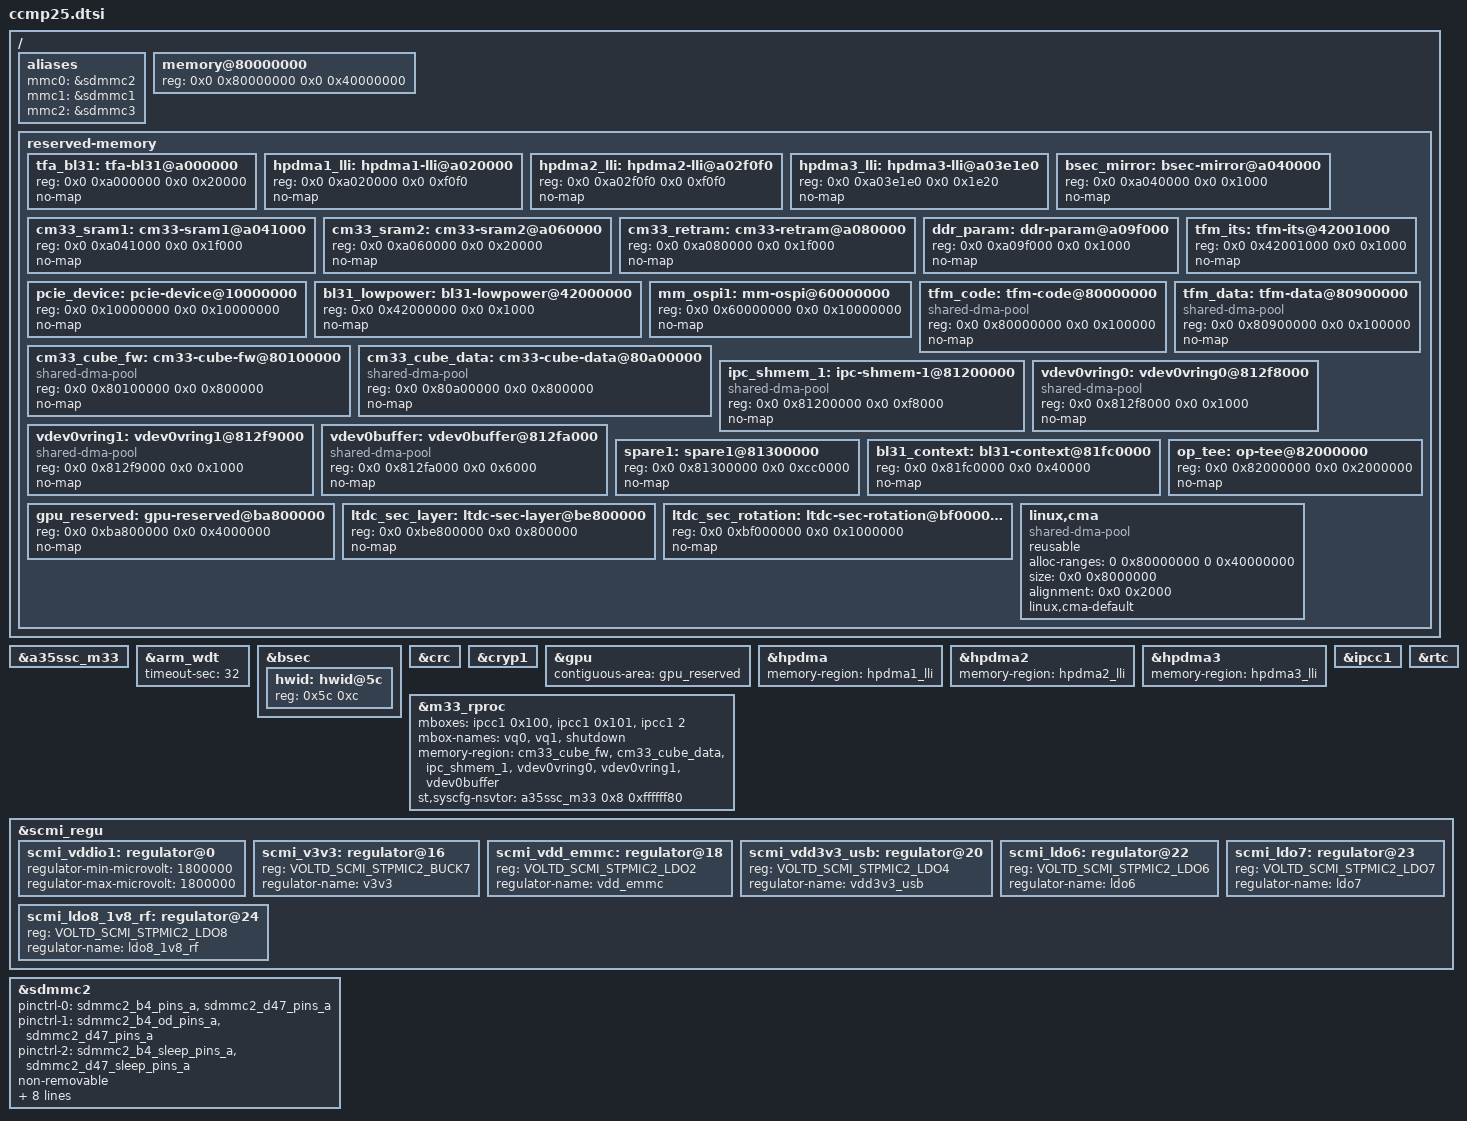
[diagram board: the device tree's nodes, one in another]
// SPDX-License-Identifier: (GPL-2.0-or-later OR BSD-3-Clause)
/*
 * Copyright (C) STMicroelectronics 2023 - All Rights Reserved
 * Copyright (C) 2024, Digi International Inc - All Rights Reserved
 */

#include <dt-bindings/gpio/gpio.h>
#include <dt-bindings/input/input.h>
#include <dt-bindings/leds/common.h>
#include <dt-bindings/regulator/st,stm32mp25-regulator.h>
#include "stm32mp255.dtsi"
#include "stm32mp25xf.dtsi"
#include "stm32mp25-pinctrl.dtsi"
#include "stm32mp25xxai-pinctrl.dtsi"

/ {
	aliases {
		mmc0 = &sdmmc2; /* eMMC */
		mmc1 = &sdmmc1; /* Wireless */
		mmc2 = &sdmmc3; /* Micro SD */
	};

	memory@80000000 {
		device_type = "memory";
		reg = <0x0 0x80000000 0x0 0x40000000>;
	};

	reserved-memory {
		#address-cells = <2>;
		#size-cells = <2>;
		ranges;

		/* Internal RAM reserved memory declaration */
		tfa_bl31: tfa-bl31@a000000 {
			reg = <0x0 0xa000000 0x0 0x20000>;
			no-map;
		};

		hpdma1_lli: hpdma1-lli@a020000 {
			reg = <0x0 0xa020000 0x0 0xf0f0>;
			no-map;
		};

		hpdma2_lli: hpdma2-lli@a02f0f0 {
			reg = <0x0 0xa02f0f0 0x0 0xf0f0>;
			no-map;
		};

		hpdma3_lli: hpdma3-lli@a03e1e0 {
			reg = <0x0 0xa03e1e0 0x0 0x1e20>;
			no-map;
		};

		bsec_mirror: bsec-mirror@a040000 {
			reg = <0x0 0xa040000 0x0 0x1000>;
			no-map;
		};

		cm33_sram1: cm33-sram1@a041000 {
			reg = <0x0 0xa041000 0x0 0x1f000>;
			no-map;
		};

		cm33_sram2: cm33-sram2@a060000 {
			reg = <0x0 0xa060000 0x0 0x20000>;
			no-map;
		};

		cm33_retram: cm33-retram@a080000 {
			reg = <0x0 0xa080000 0x0 0x1f000>;
			no-map;
		};

		ddr_param: ddr-param@a09f000 {
			reg = <0x0 0xa09f000 0x0 0x1000>;
			no-map;
		};

		/* PCIe reserved memory declaration */
		pcie_device: pcie-device@10000000 {
			reg = <0x0 0x10000000 0x0 0x10000000>;
			no-map;
		};

		/* Backup RAM reserved memory declaration */
		bl31_lowpower: bl31-lowpower@42000000 {
			reg = <0x0 0x42000000 0x0 0x1000>;
			no-map;
		};

		tfm_its: tfm-its@42001000 {
			reg = <0x0 0x42001000 0x0 0x1000>;
			no-map;
		};

		/* Octo Memory Manager reserved memory declaration */
		mm_ospi1: mm-ospi@60000000 {
			reg = <0x0 0x60000000 0x0 0x10000000>;
			no-map;
		};

		/* DDR reserved memory declaration */
		tfm_code: tfm-code@80000000 {
			compatible = "shared-dma-pool";
			reg = <0x0 0x80000000 0x0 0x100000>; /* 1 MiB */
			no-map;
		};

		cm33_cube_fw: cm33-cube-fw@80100000 {
			compatible = "shared-dma-pool";
			reg = <0x0 0x80100000 0x0 0x800000>; /* 8 MiB */
			no-map;
		};

		tfm_data: tfm-data@80900000 {
			compatible = "shared-dma-pool";
			reg = <0x0 0x80900000 0x0 0x100000>; /* 1 MiB */
			no-map;
		};

		cm33_cube_data: cm33-cube-data@80a00000 {
			compatible = "shared-dma-pool";
			reg = <0x0 0x80a00000 0x0 0x800000>; /* 8 MiB */
			no-map;
		};

		ipc_shmem_1: ipc-shmem-1@81200000 {
			compatible = "shared-dma-pool";
			reg = <0x0 0x81200000 0x0 0xf8000>; /* 992 KiB */
			no-map;
		};

		vdev0vring0: vdev0vring0@812f8000 {
			compatible = "shared-dma-pool";
			reg = <0x0 0x812f8000 0x0 0x1000>; /* 4 KiB */
			no-map;
		};

		vdev0vring1: vdev0vring1@812f9000 {
			compatible = "shared-dma-pool";
			reg = <0x0 0x812f9000 0x0 0x1000>; /* 4 KiB */
			no-map;
		};

		vdev0buffer: vdev0buffer@812fa000 {
			compatible = "shared-dma-pool";
			reg = <0x0 0x812fa000 0x0 0x6000>; /* 24 KiB */
			no-map;
		};

		spare1: spare1@81300000 {
			reg = <0x0 0x81300000 0x0 0xcc0000>; /* 12,75 MiB */
			no-map;
		};

		bl31_context: bl31-context@81fc0000 {
			reg = <0x0 0x81fc0000 0x0 0x40000>; /* 256 KiB */
			no-map;
		};

		op_tee: op-tee@82000000 {
			reg = <0x0 0x82000000 0x0 0x2000000>; /* 32 MiB */
			no-map;
		};

		gpu_reserved: gpu-reserved@ba800000 {
			reg = <0x0 0xba800000 0x0 0x4000000>; /* 64 MiB */
			no-map;
		};

		ltdc_sec_layer: ltdc-sec-layer@be800000 {
			reg = <0x0 0xbe800000 0x0 0x800000>; /* 8 MiB */
			no-map;
		};

		ltdc_sec_rotation: ltdc-sec-rotation@bf000000 {
			reg = <0x0 0xbf000000 0x0 0x1000000>; /* 16 MiB */
			no-map;
		};

		/* global autoconfigured region for contiguous allocations */
		linux,cma {
			compatible = "shared-dma-pool";
			reusable;
			alloc-ranges = <0 0x80000000 0 0x40000000>;
			size = <0x0 0x8000000>; /* 128 MiB */
			alignment = <0x0 0x2000>;
			linux,cma-default;
		};
	};
};

&a35ssc_m33 {
	status = "okay";
};

&arm_wdt {
	timeout-sec = <32>;
	status = "okay";
};

&bsec {
	hwid: hwid@5c {
		reg = <0x5c 0xc>;
	};
};

&crc {
	status = "okay";
};

&cryp1 {
	status = "okay";
};

&gpu {
	contiguous-area = <&gpu_reserved>;
	status = "okay";
};

&hpdma {
	memory-region = <&hpdma1_lli>;
};

&hpdma2 {
	memory-region = <&hpdma2_lli>;
};

&hpdma3 {
	memory-region = <&hpdma3_lli>;
};

&ipcc1 {
	status = "okay";
};

&m33_rproc {
	mboxes = <&ipcc1 0x100>, <&ipcc1 0x101>, <&ipcc1 2>;
	mbox-names = "vq0", "vq1", "shutdown";
	memory-region = <&cm33_cube_fw>, <&cm33_cube_data>,
			<&ipc_shmem_1>, <&vdev0vring0>,
			<&vdev0vring1>, <&vdev0buffer>;
	st,syscfg-nsvtor = <&a35ssc_m33 0x8 0xffffff80>;
	status = "okay";
};

&rtc {
	status = "okay";
};

&scmi_regu {
	scmi_vddio1: regulator@0 {
		regulator-min-microvolt = <1800000>;
		regulator-max-microvolt = <1800000>;
	};
	scmi_v3v3: regulator@16 {
		reg = <VOLTD_SCMI_STPMIC2_BUCK7>;
		regulator-name = "v3v3";
	};
	scmi_vdd_emmc: regulator@18 {
		reg = <VOLTD_SCMI_STPMIC2_LDO2>;
		regulator-name = "vdd_emmc";
	};
	scmi_vdd3v3_usb: regulator@20 {
		reg = <VOLTD_SCMI_STPMIC2_LDO4>;
		regulator-name = "vdd3v3_usb";
	};
	scmi_ldo6: regulator@22 {
		reg = <VOLTD_SCMI_STPMIC2_LDO6>;
		regulator-name = "ldo6";
	};
	scmi_ldo7: regulator@23 {
		reg = <VOLTD_SCMI_STPMIC2_LDO7>;
		regulator-name = "ldo7";
	};
	scmi_ldo8_1v8_rf: regulator@24 {
		reg = <VOLTD_SCMI_STPMIC2_LDO8>;
		regulator-name = "ldo8_1v8_rf";
	};
};

/* eMMC */
&sdmmc2 {
	pinctrl-names = "default", "opendrain", "sleep";
	pinctrl-0 = <&sdmmc2_b4_pins_a &sdmmc2_d47_pins_a>;
	pinctrl-1 = <&sdmmc2_b4_od_pins_a &sdmmc2_d47_pins_a>;
	pinctrl-2 = <&sdmmc2_b4_sleep_pins_a &sdmmc2_d47_sleep_pins_a>;
	non-removable;
	no-sd;
	no-sdio;
	st,neg-edge;
	bus-width = <8>;
	vmmc-supply = <&scmi_vdd_emmc>; /* LDO2 - VDD_EMMC */
	vqmmc-supply = <&scmi_vddio2>; /* BUCK5 - 1V8 - VDDIO2 */
	mmc-ddr-1_8v;
	mmc-hs200-1_8v;
	status = "okay";
};
